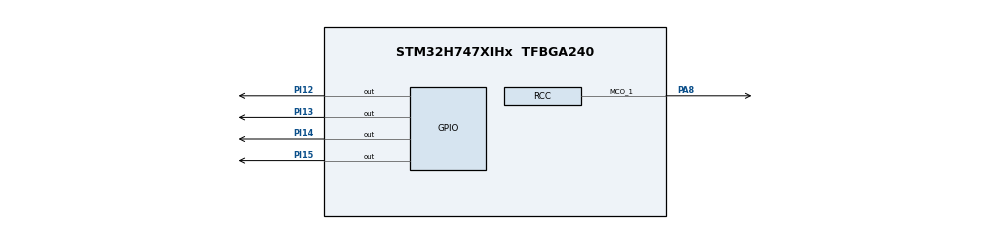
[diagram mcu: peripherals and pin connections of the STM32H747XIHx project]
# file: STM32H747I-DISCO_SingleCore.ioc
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CORTEX_M7.CPU_DCache=Enabled
CORTEX_M7.CPU_ICache=Enabled
CortexM4.IPs=BDMA,DMA,FATFS_M4\:I,FREERTOS_M4\:I,IWDG2\:I,MDMA,NVIC2\:I,RCC,USB_DEVICE_M4\:I,USB_HOST_M4\:I,WWDG2\:I,USART1,USB_OTG_HS\:I,SPI2\:I,ADC1\:I,ADC3\:I,FMC\:I,QUADSPI\:I,SAI1\:I,ETH\:I,SPI5\:I,TIM8\:I,UART8\:I,DCMI\:I,RTC\:I,SDMMC1\:I,SPDIFRX1\:I,HDMI_CEC\:I,TIM13\:I,TIM3\:I,DEBUG,PDM2PCM_M4\:I,PWR,RESMGR_UTILITY,SYS_M4\:I,CORTEX_M4\:I,OPENAMP_M4\:I,VREFBUF
CortexM4.Pins=PI12,PI13
CortexM7.IPs=BDMA\:I,DMA\:I,FATFS_M7\:I,FREERTOS_M7\:I,IWDG1\:I,MDMA\:I,NVIC1\:I,RCC\:I,USB_DEVICE_M7\:I,USB_HOST_M7\:I,WWDG1\:I,USART1\:I,CORTEX_M7\:I,DEBUG\:I,PDM2PCM_M7\:I,PWR\:I,RESMGR_UTILITY\:I,SYS\:I,OPENAMP_M7\:I,VREFBUF\:I
CortexM7.Pins=PI14,PI15
Mcu.Family=STM32H7
Mcu.Name=STM32H747XIHx
Mcu.Package=TFBGA240
NVIC1.PriorityGroup=NVIC_PRIORITYGROUP_4
NVIC2.PriorityGroup=NVIC_PRIORITYGROUP_4
PA13\ (JTMS/SWDIO).Mode=Trace_Asynchronous_SW
PA13\ (JTMS/SWDIO).PinAttribute=CortexM7
PA13\ (JTMS/SWDIO).Signal=DEBUG_JTMS-SWDIO
PA14\ (JTCK/SWCLK).Mode=Trace_Asynchronous_SW
PA14\ (JTCK/SWCLK).PinAttribute=CortexM7
PA14\ (JTCK/SWCLK).Signal=DEBUG_JTCK-SWCLK
PA8.Mode=Clock-out-1
PA8.PinAttribute=CortexM7
PA8.Signal=RCC_MCO_1
PB3\ (JTDO/TRACESWO).Mode=Trace_Asynchronous_SW
PB3\ (JTDO/TRACESWO).PinAttribute=CortexM7
PB3\ (JTDO/TRACESWO).Signal=DEBUG_JTDO-SWO
PC14-OSC32_IN\ (OSC32_IN).Mode=LSE-External-Oscillator
PC14-OSC32_IN\ (OSC32_IN).PinAttribute=CortexM7
PC14-OSC32_IN\ (OSC32_IN).Signal=RCC_OSC32_IN
PC15-OSC32_OUT\ (OSC32_OUT).Mode=LSE-External-Oscillator
PC15-OSC32_OUT\ (OSC32_OUT).PinAttribute=CortexM7
PC15-OSC32_OUT\ (OSC32_OUT).Signal=RCC_OSC32_OUT
PH0-OSC_IN\ (PH0).Mode=HSE-External-Clock-Source
PH0-OSC_IN\ (PH0).PinAttribute=CortexM7
PH0-OSC_IN\ (PH0).Signal=RCC_OSC_IN
PI12.PinAttribute=CortexM4
PI12.Signal=GPIO_Output
PI13.PinAttribute=CortexM4
PI13.PinState=GPIO_PIN_SET
PI13.Signal=GPIO_Output
PI14.PinAttribute=CortexM7
PI14.Signal=GPIO_Output
PI15.PinAttribute=CortexM7
PI15.Signal=GPIO_Output
ProjectManager.HeapSize=M4-0x200,M7-0x200
ProjectManager.StackSize=M4-0x400,M7-0x400
ProjectManager.TargetToolchain=STM32CubeIDE
RCC.ADCCLockSelection=RCC_ADCCLKSOURCE_PLL2
RCC.ADCFreq_Value=75000000
RCC.APB1Freq_Value=100000000
RCC.APB2Freq_Value=100000000
RCC.APB3Freq_Value=100000000
RCC.APB4Freq_Value=100000000
RCC.CSI_VALUE=4000000
RCC.CortexFreq_Value=400000000
RCC.Cortex_Div=SYSTICK_CLKSOURCE_HCLK
RCC.Cortex_DivARG=SystemCoreClock/1000
RCC.D1CPRE=RCC_SYSCLK_DIV1
RCC.D1PPRE=RCC_APB3_DIV2
RCC.D2PPRE1=RCC_APB1_DIV2
RCC.D2PPRE2=RCC_APB2_DIV2
RCC.D3PPRE=RCC_APB4_DIV2
RCC.DIVM1=5
RCC.DIVM2=2
RCC.DIVM3=32
RCC.DIVN1=160
RCC.DIVN2=12
RCC.DIVN3=129
RCC.DIVP1=2
RCC.DIVP2=2
RCC.DIVP3=2
RCC.DIVQ1=5
RCC.DIVQ2=2
RCC.DIVQ3=2
RCC.DIVR1=2
RCC.DIVR2=2
RCC.DIVR3=2
RCC.DSICLockSelection=RCC_DSICLKSOURCE_PHY
RCC.DSIPHY_Div=8
RCC.DSITX_Div=4
RCC.DSI_PHY_VALUE=12288000
RCC.EXTERNAL_CLOCK_VALUE=12288000
RCC.FLatency-AdvancedSettings=FLASH_LATENCY_0
RCC.HCLKFreq_Value=200000000
RCC.HPRE=RCC_HCLK_DIV2
RCC.HSE_VALUE=25000000
RCC.HSIDiv=RCC_PLLSAIDIVR_1
RCC.HSI_VALUE=64000000
RCC.I2C4CLockSelection=RCC_I2C4CLKSOURCE_D3PCLK1
RCC.LPTIM2CLockSelection=RCC_LPTIM2CLKSOURCE_D3PCLK1
RCC.LPTIM345CLockSelection=RCC_LPTIM345CLKSOURCE_D3PCLK1
RCC.LPUART1CLockSelection=RCC_LPUART1CLKSOURCE_D3PCLK1
RCC.PLL1_VCI_Range-AdvancedSettings=RCC_PLL1VCIRANGE_0
RCC.PLL2FRACN=0
RCC.PLL2_VCI_Range-AdvancedSettings=RCC_PLL2VCIRANGE_0
RCC.PLL2_VCO_SEL-AdvancedSettings=RCC_PLL2VCOWIDE
RCC.PLL3FRACN=0
RCC.PLLDSIDev=2
RCC.PLLDSIIDF=DSI_PLL_IN_DIV1
RCC.PLLDSIMult=2
RCC.PLLDSINDIV=20
RCC.PLLDSIODF=DSI_PLL_OUT_DIV1
RCC.PLLFRACN=0
RCC.PLLSourceVirtual=RCC_PLLSOURCE_HSE
RCC.PWR_Regulator_Voltage_Scale=PWR_REGULATOR_VOLTAGE_SCALE1
RCC.RC48_VALUE=48000000
RCC.RCC_MCO1Source=RCC_MCO1SOURCE_HSI
RCC.RCC_MCO2Source=RCC_MCO2SOURCE_SYSCLK
RCC.RCC_MCODiv2=RCC_MCODIV_1
RCC.RCC_RTC_Clock_Source_FROM_HSE=RCC_RTCCLKSOURCE_HSE_DIV2
RCC.RNGCLockSelection=RCC_RNGCLKSOURCE_HSI48
RCC.SAI4ACLockSelection=RCC_SAI4ACLKSOURCE_PLL
RCC.SAI4BCLockSelection=RCC_SAI4BCLKSOURCE_PLL
RCC.SPI6CLockSelection=RCC_SPI6CLKSOURCE_D3PCLK1
RCC.SYSCLKFreq_VALUE=400000000
RCC.SYSCLKSource=RCC_SYSCLKSOURCE_PLLCLK
RCC.SupplySource=PWR_DIRECT_SMPS_SUPPLY
RCC.USART16CLockSelection=RCC_USART16CLKSOURCE_D2PCLK2
RCC.USART234578CLockSelection=RCC_USART234578CLKSOURCE_D2PCLK1
RCC.USBFreq_Value=160000000
VP_SYS_M4_VS_Systick.Mode=SysTick
board=STM32H747I-DISCO

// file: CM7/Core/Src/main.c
/* USER CODE BEGIN Header */
/**
  ******************************************************************************
  * @file           : main.c
  * @brief          : Main program body
  ******************************************************************************
  * @attention
  *
  * <h2><center>&copy; Copyright (c) 2021 STMicroelectronics.
  * All rights reserved.</center></h2>
  *
  * This software component is licensed by ST under BSD 3-Clause license,
  * the "License"; You may not use this file except in compliance with the
  * License. You may obtain a copy of the License at:
  *                        opensource.org/licenses/BSD-3-Clause
  *
  ******************************************************************************
  */
/* USER CODE END Header */
#include "main.h"

/* USER CODE BEGIN PD */

#ifndef HSEM_ID_0
#define HSEM_ID_0 (0U) /* HW semaphore 0*/
#endif
/* USER CODE END PD */

void SystemClock_Config(void);
static void MX_GPIO_Init(void);

int main(void)
{
/* USER CODE BEGIN Boot_Mode_Sequence_0 */
  int32_t timeout;
/* USER CODE END Boot_Mode_Sequence_0 */

  /* Enable I-Cache---------------------------------------------------------*/
  SCB_EnableICache();

  /* Enable D-Cache---------------------------------------------------------*/
  SCB_EnableDCache();

/* USER CODE BEGIN Boot_Mode_Sequence_1 */
  /* Wait until CPU2 boots and enters in stop mode or timeout*/
  timeout = 0xFFFF;
  while((__HAL_RCC_GET_FLAG(RCC_FLAG_D2CKRDY) != RESET) && (timeout-- > 0));
  if ( timeout < 0 )
  {
  Error_Handler();
  }
/* USER CODE END Boot_Mode_Sequence_1 */
  /* MCU Configuration--------------------------------------------------------*/

  /* Reset of all peripherals, Initializes the Flash interface and the Systick. */
  HAL_Init();

  /* Configure the system clock */
  SystemClock_Config();
/* USER CODE BEGIN Boot_Mode_Sequence_2 */
/* When system initialization is finished, Cortex-M7 will release Cortex-M4 by means of
HSEM notification */
/*HW semaphore Clock enable*/
__HAL_RCC_HSEM_CLK_ENABLE();
/*Take HSEM */
HAL_HSEM_FastTake(HSEM_ID_0);
/*Release HSEM in order to notify the CPU2(CM4)*/
HAL_HSEM_Release(HSEM_ID_0,0);
/* wait until CPU2 wakes up from stop mode */
timeout = 0xFFFF;
while((__HAL_RCC_GET_FLAG(RCC_FLAG_D2CKRDY) == RESET) && (timeout-- > 0));
if ( timeout < 0 )
{
Error_Handler();
}
/* USER CODE END Boot_Mode_Sequence_2 */

  /* Initialize all configured peripherals */
  MX_GPIO_Init();

  /* Infinite loop */
  /* USER CODE BEGIN WHILE */
  while (1)
  {
	  HAL_GPIO_TogglePin(GPIOI, GPIO_PIN_15);
	  HAL_Delay(200);

    /* USER CODE END WHILE */

  }
}

void SystemClock_Config(void)
{
  RCC_OscInitTypeDef RCC_OscInitStruct = {0};
  RCC_ClkInitTypeDef RCC_ClkInitStruct = {0};

  /** Supply configuration update enable
  */
  HAL_PWREx_ConfigSupply(PWR_DIRECT_SMPS_SUPPLY);

  /** Configure the main internal regulator output voltage
  */
  __HAL_PWR_VOLTAGESCALING_CONFIG(PWR_REGULATOR_VOLTAGE_SCALE1);

  while(!__HAL_PWR_GET_FLAG(PWR_FLAG_VOSRDY)) {}

  /** Initializes the RCC Oscillators according to the specified parameters
  * in the RCC_OscInitTypeDef structure.
  */
  RCC_OscInitStruct.OscillatorType = RCC_OSCILLATORTYPE_HSI|RCC_OSCILLATORTYPE_HSE;
  RCC_OscInitStruct.HSEState = RCC_HSE_BYPASS;
  RCC_OscInitStruct.HSIState = RCC_HSI_DIV1;
  RCC_OscInitStruct.HSICalibrationValue = RCC_HSICALIBRATION_DEFAULT;
  RCC_OscInitStruct.PLL.PLLState = RCC_PLL_ON;
  RCC_OscInitStruct.PLL.PLLSource = RCC_PLLSOURCE_HSE;
  RCC_OscInitStruct.PLL.PLLM = 5;
  RCC_OscInitStruct.PLL.PLLN = 160;
  RCC_OscInitStruct.PLL.PLLP = 2;
  RCC_OscInitStruct.PLL.PLLQ = 5;
  RCC_OscInitStruct.PLL.PLLR = 2;
  RCC_OscInitStruct.PLL.PLLRGE = RCC_PLL1VCIRANGE_2;
  RCC_OscInitStruct.PLL.PLLVCOSEL = RCC_PLL1VCOWIDE;
  RCC_OscInitStruct.PLL.PLLFRACN = 0;
  if (HAL_RCC_OscConfig(&RCC_OscInitStruct) != HAL_OK)
  {
    Error_Handler();
  }

  /** Initializes the CPU, AHB and APB buses clocks
  */
  RCC_ClkInitStruct.ClockType = RCC_CLOCKTYPE_HCLK|RCC_CLOCKTYPE_SYSCLK
                              |RCC_CLOCKTYPE_PCLK1|RCC_CLOCKTYPE_PCLK2
                              |RCC_CLOCKTYPE_D3PCLK1|RCC_CLOCKTYPE_D1PCLK1;
  RCC_ClkInitStruct.SYSCLKSource = RCC_SYSCLKSOURCE_PLLCLK;
  RCC_ClkInitStruct.SYSCLKDivider = RCC_SYSCLK_DIV1;
  RCC_ClkInitStruct.AHBCLKDivider = RCC_HCLK_DIV2;
  RCC_ClkInitStruct.APB3CLKDivider = RCC_APB3_DIV2;
  RCC_ClkInitStruct.APB1CLKDivider = RCC_APB1_DIV2;
  RCC_ClkInitStruct.APB2CLKDivider = RCC_APB2_DIV2;
  RCC_ClkInitStruct.APB4CLKDivider = RCC_APB4_DIV2;

  if (HAL_RCC_ClockConfig(&RCC_ClkInitStruct, FLASH_LATENCY_2) != HAL_OK)
  {
    Error_Handler();
  }
  HAL_RCC_MCOConfig(RCC_MCO1, RCC_MCO1SOURCE_HSI, RCC_MCODIV_1);
}

static void MX_GPIO_Init(void)
{
  GPIO_InitTypeDef GPIO_InitStruct = {0};

  /* GPIO Ports Clock Enable */
  __HAL_RCC_GPIOA_CLK_ENABLE();
  __HAL_RCC_GPIOC_CLK_ENABLE();
  __HAL_RCC_GPIOB_CLK_ENABLE();
  __HAL_RCC_GPIOI_CLK_ENABLE();
  __HAL_RCC_GPIOH_CLK_ENABLE();

  /*Configure GPIO pin Output Level */
  HAL_GPIO_WritePin(GPIOI, GPIO_PIN_14|GPIO_PIN_15, GPIO_PIN_RESET);

  /*Configure GPIO pin : PA8 */
  GPIO_InitStruct.Pin = GPIO_PIN_8;
  GPIO_InitStruct.Mode = GPIO_MODE_AF_PP;
  GPIO_InitStruct.Pull = GPIO_NOPULL;
  GPIO_InitStruct.Speed = GPIO_SPEED_FREQ_LOW;
  GPIO_InitStruct.Alternate = GPIO_AF0_MCO;
  HAL_GPIO_Init(GPIOA, &GPIO_InitStruct);

  /*Configure GPIO pins : PI14 PI15 */
  GPIO_InitStruct.Pin = GPIO_PIN_14|GPIO_PIN_15;
  GPIO_InitStruct.Mode = GPIO_MODE_OUTPUT_PP;
  GPIO_InitStruct.Pull = GPIO_NOPULL;
  GPIO_InitStruct.Speed = GPIO_SPEED_FREQ_LOW;
  HAL_GPIO_Init(GPIOI, &GPIO_InitStruct);

}

void Error_Handler(void)
{
  __disable_irq();
  while (1)
  {
  }
}
